# D1H register map
Vendor: Allwinner; File version: 1.0
Registers are 32-bit, read-write, reset 0x0 unless marked. A register's access mark holds for its fields unless they carry their own. Offsets are from the block's base; [hi:lo] are bit positions; {n}, {i} and the like mark numbered series.

## TVD_TOP — Television Decoder TOP
Base 0x05C00000
0x00 tvd_top_map
{0x4+4i} tvd_3d_ctl{i} (i=1..5) — TVD 3D DMA CONTROL Register{i}
{0x24+0x20*i} tvd_top_ctl{i} (i=0..3) — TVD TOP CONTROL Register
{0x28+0x20*i} tvd_adc_ctl{i} (i=0..3) — TVD ADC CONTROL Register
{0x2C+0x20*i} tvd_adc_cfg{i} (i=0..3) — TVD ADC CONFIGURATION Register

## TVD0 — Television Decoder
Base 0x05C01000
0x00 tvd_en — TVD MODULE CONTROL Register
0x04 tvd_mode — TVD MODE CONTROL Register
0x08 tvd_clamp_agc1 — TVD CLAMP And AGC CONTROL Register1
0x0C tvd_clamp_agc2 — TVD CLAMP And AGC CONTROL Register2
{0xC+4i} tvd_hlock{i} (i=1..5) — TVD HLOCK CONTROL Register{i}
0x24 tvd_vlock1 — TVD VLOCK CONTROL Register1
0x28 tvd_vlock2 — TVD VLOCK CONTROL Register2
0x30 tvd_clock1 — TVD CHROMA LOCK CONTROL Register1
0x34 tvd_clock2 — TVD CHROMA LOCK CONTROL Register2
0x40 tvd_yc_sep1 — TVD YC SEPERATION CONROL Register1
0x44 tvd_yc_sep2 — TVD YC SEPERATION CONROL Register2
{0x4C+4i} tvd_enhance{i} (i=1..3) — TVD ENHANCEMENT CONTROL Register{i}
{0x5C+4i} tvd_wb{i} (i=1..4) — TVD WB DMA CONTROL Register{i}
0x80 tvd_irq_ctl — TVD DMA Interrupt Control Register
0x90 tvd_irq_status — TVD DMA Interrupt Status Register
0x100 tvd_debug1 — TVD DEBUG CONTROL Register1
{0x17C+4i} tvd_status{i} (i=1..6) — TVD DEBUG STATUS Register{i}

## DMIC
Base 0x02031000
0x00 dmic_en — DMIC Enable Control Register
0x04 dmic_sr — DMIC Sample Rate Register
0x08 dmic_ctr — DMIC Control Register
0x10 dmic_data
0x14 dmic_intc — DMIC Interrupt Control Register
0x18 dmic_ints — DMIC Interrupt Status Register
0x1C dmic_rxfifo_ctr — DMIC RXFIFO Control Register
0x20 dmic_rxfifo_sta — DMIC RXFIFO Status Register
0x24 dmic_ch_num — DMIC Channel Numbers Register
0x28 dmic_ch_map — DMIC Channel Mapping Register
0x2C dmic_cnt — DMIC Counter Register
0x30 data0_data1_vol_ctr — Data0 and Data1 Volume Control Register
0x34 data2_data3_vol_ctr — Data2 And Data3 Volume Control Register
0x38 hpf_en_ctr — High Pass Filter Enable Control Register
0x3C hpf_coef — High Pass Filter Coefficient Register
0x40 hpf_gain — High Pass Filter Gain Register

## OWA — One Wire Audio
Base 0x02036000
0x00 owa_gen_ctl — OWA General Control Register
0x04 owa_tx_cfig — OWA TX Configuration Register
0x08 owa_rx_cfig — OWA RX Configuration Register
0x0C owa_ista — OWA Interrupt Status Register
0x10 owa_rxfifo
0x14 owa_fctl — OWA FIFO Control Register
0x18 owa_fsta — OWA FIFO Status Register
0x1C owa_int — OWA Interrupt Control Register
0x20 owa_tx_fifo
0x24 owa_tx_cnt — OWA TX Counter Register
0x28 owa_rx_cnt — OWA RX Counter Register
0x2C owa_tx_chsta0 — OWA TX Channel Status Register0
0x30 owa_tx_chsta1 — OWA TX Channel Status Register1
0x34 owa_rxchsta0 — OWA RX Channel Status Register0
0x38 owa_rxchsta1 — OWA RX Channel Status Register1
0x40 owa_exp_ctl — OWA Expand Control Register
0x44 owa_exp_ista — OWA Expand Interrupt Status Register
0x48 owa_exp_info_0 — OWA Expand Infomation Register0
0x4C owa_exp_info_1 — OWA Expand Infomation Register1
0x50 owa_exp_dbg_0 — OWA Expand Debug Register0
0x54 owa_exp_dbg_1 — OWA Expand Debug Register1

## TPADC — Touch Panel ADC
Base 0x02009C00
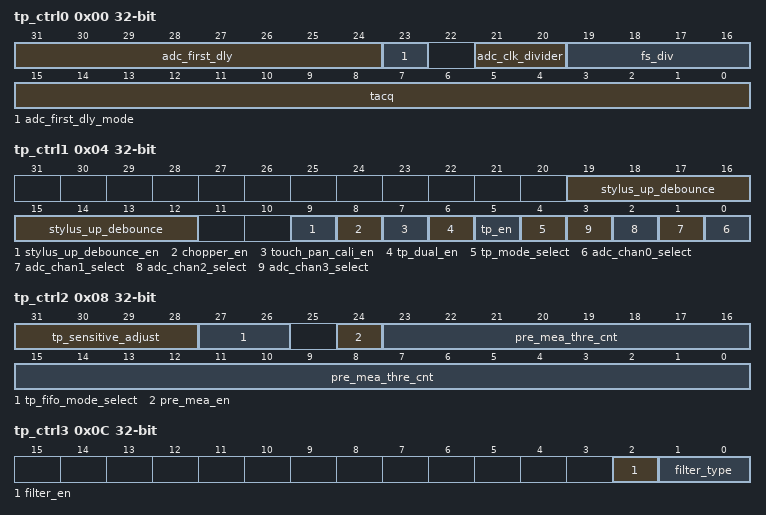
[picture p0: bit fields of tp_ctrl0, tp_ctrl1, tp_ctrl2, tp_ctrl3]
0x00 tp_ctrl0 — TP Control Register 0
  [31:24] adc_first_dly — ADC First Convert Delay Time (T_FCDT) Setting
  [23] adc_first_dly_mode — ADC First Convert Delay Mode Select
    0=C16 (CLK_IN / 16); 1=C16_256 (CLK_IN / 16 * 256)
  [21:20] adc_clk_divider — ADC Clock Divider (CLK_IN)
    0=C2 (CLK / 2); 1=C3 (CLK / 3); 2=C6 (CLK / 6); 3=C1 (CLK / 1)
  [19:16] fs_div — ADC Sample Frequency Divider
    {v}=C2P{v} (CLK_IN / 2 ^ (20 - {v})) (v=0..15)
  [15:0] tacq — Touch panel ADC acquire time
0x04 tp_ctrl1 — TP Control Register 1
  [19:12] stylus_up_debounce — Stylus Up Debounce Time Setting
  [9] stylus_up_debounce_en — Stylus Up Debounce Function Select
    0=DISABLE; 1=ENABLE
  [8] chopper_en — T-sensor Chopping Enable
    0=DISABLE; 1=ENABLE
  [7] touch_pan_cali_en — Touch Panel Calibration
    1=START
  [6] tp_dual_en — Touch Panel Double Point Enable
    0=DISABLE; 1=ENABLE
  [5] tp_en — TP Function Enable
    0=DISABLE; 1=ENABLE
  [4] tp_mode_select — Touch Panel Mode and Auxiliary ADC Mode Select
    0=TP; 1=AUXILIARY_ADC
  [n] adc_chan{n}_select (n=0..3) — Analog Input Channel Select
    0=DISABLE; 1=ENABLE
0x08 tp_ctrl2 — TP Control Register 2
  [31:28] tp_sensitive_adjust — Internal Pull-up Resistor Control
  [27:26] tp_fifo_mode_select — TP Access Data Mode Select
    0=X1Y1 (FIFO store X1 Y1 data for single touch no pressure mode); 1=X1Y1D_XD_Y (FIFO store X1 Y1 ΔX ΔY data for dual touch no pressure mode); 2=X1Y1X2Y2 (FIFO store X1 Y1 X2 Y2 data for dual touch no pressure mode); 3=X1Y1X2Y2Z1Z2 (FIFO store X1 Y1 X2 Y2 Z1 Z2 data for dual touch and pressure mode)
  [24] pre_mea_en — TP Pressure Measurement Enable Control
    0=DISABLE; 1=ENABLE
  [23:0] pre_mea_thre_cnt — TP Pressure Measurement Threshold Control
0x0C tp_ctrl3 — TP Control Register 3
  [2] filter_en — Filter Enable
    0=DISABLE; 1=ENABLE
  [1:0] filter_type
    0=T42 (4 / 2); 1=T53 (5 / 3); 2=T84 (8 / 4); 3=T168 (16 / 8)
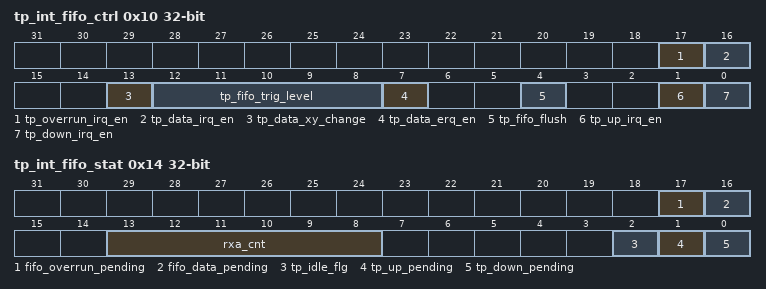
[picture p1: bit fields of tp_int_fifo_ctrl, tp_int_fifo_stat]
0x10 tp_int_fifo_ctrl — TP Interrupt FIFO Control Register
  [17] tp_overrun_irq_en — TP FIFO Overrun Interrupt Enable
    0=DISABLE; 1=ENABLE
  [16] tp_data_irq_en — TP FIFO Data Interrupt Enable
    0=DISABLE; 1=ENABLE
  [13] tp_data_xy_change — TP FIFO XY Data Interchange Function Select
    0=DISABLE; 1=ENABLE
  [12:8] tp_fifo_trig_level — TP FIFO Data Available Trigger Level
  [7] tp_data_erq_en — TP FIFO Data Available DRQ Enable
    0=DISABLE; 1=ENABLE
  [4] tp_fifo_flush
    1=FLUSH
  [1] tp_up_irq_en — TP Last Touch (Stylus UP) IRQ Enable
    0=DISABLE; 1=ENABLE
  [0] tp_down_irq_en — TP First Touch (Stylus DOWN) IRQ Enable
    0=DISABLE; 1=ENABLE
0x14 tp_int_fifo_stat — TP Interrupt FIFO Status Register
  [17] fifo_overrun_pending write-1-clears — TP FIFO Overrun Pending
    0=NO_PENDING; 1=PENDING
  [16] fifo_data_pending write-1-clears — TP FIFO Data Available Pending
    0=NO_PENDING; 1=PENDING
  [13:8] rxa_cnt ro — TP FIFO Available Sample Word Count
  [2] tp_idle_flg ro — TP Idle Flag
    0=IDLE; 1=NOT_IDLE
  [1] tp_up_pending write-1-clears — TP Last Touch (Stylus UP) Pending
    0=NO_PENDING; 1=PENDING
  [0] tp_down_pending write-1-clears — TP First Touch (Stylus DOWN) Pending
    0=NO_PENDING; 1=PENDING
0x1C tp_cali_data — TP Calibration Data Register
  [11:0] tp_cdat — TP Common Data
0x24 tp_data ro
  [11:0] tp_data
